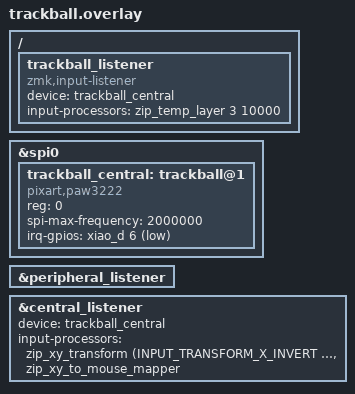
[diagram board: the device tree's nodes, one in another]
&spi0 {
    status = "okay";

    trackball_central: trackball@1 {
        status = "okay";
        compatible = "pixart,paw3222";
        reg = <0>;
        spi-max-frequency = <2000000>;
        irq-gpios = <&xiao_d 6 (GPIO_ACTIVE_LOW | GPIO_PULL_UP)>;
    };
};

/* ペリフェラル（split経由）のリスナーを有効化 */
&peripheral_listener {
    status = "okay";
};

/* 右手トラボ：マウス移動のみ */
&central_listener {
    status = "okay";
    device = <&trackball_central>;

    input-processors =
        <&zip_xy_transform (INPUT_TRANSFORM_X_INVERT | INPUT_TRANSFORM_Y_INVERT)>,
        <&zip_xy_to_mouse_mapper>;
};

/* オートマウスレイヤー */
#include <input/processors.dtsi>
/ {
    trackball_listener: trackball_listener {
        compatible = "zmk,input-listener";
        device = <&trackball_central>;

        input-processors = <&zip_temp_layer 3 10000>;
    };
};

